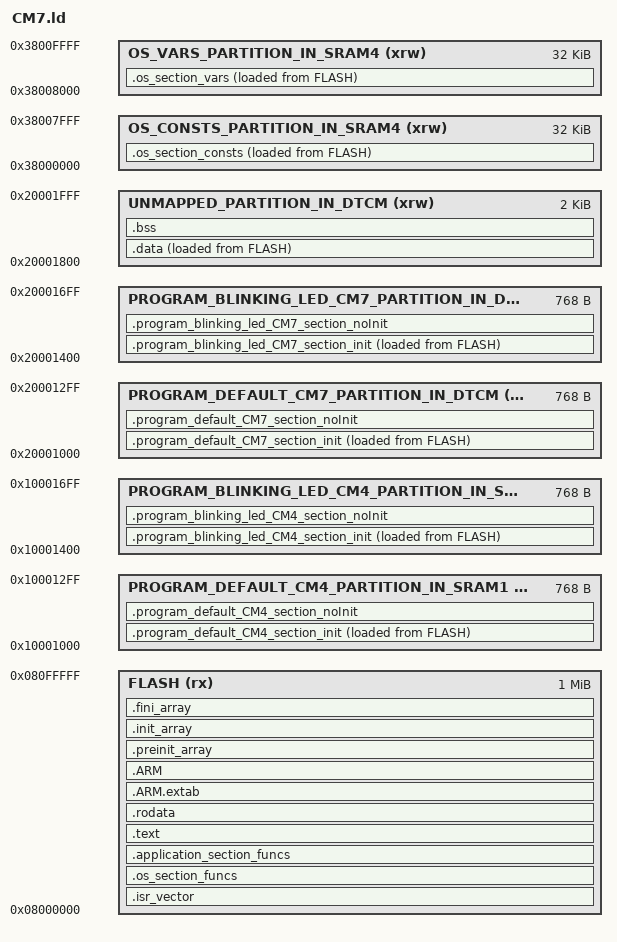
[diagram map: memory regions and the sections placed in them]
/********************************************************************************
**                                                                             **
**                       GENERATED FILE BY CosmOS CustomBox                    **
**                                                                             **
*********************************************************************************
**                       DOXYGEN DOCUMENTATION INFORMATION                     **
*****************************************************************************//**
** @file CM7.ld
*********************************************************************************
<!--                      Linker Local Group Definition                       -->
*********************************************************************************
** @brief CM7 arm gnu linker script
** @details lorem
*********************************************************************************
<!--                           Version Information                            -->
*********************************************************************************
** @version 2.0.0
** @date 2021-09-08
** @author Generated by CosmOS CustomBox
********************************************************************************/

ENTRY(Reset_Handler)

_estack = 0x20020000;

MEMORY
{
FLASH (rx)      : ORIGIN = 0x8000000, LENGTH = 0x100000
UNMAPPED_PARTITION_IN_DTCM (xrw)     : ORIGIN = 0x20001800, LENGTH = 0x0800
OS_CONSTS_PARTITION_IN_SRAM4 (xrw)     : ORIGIN = 0x38000000, LENGTH = 0x8000
OS_VARS_PARTITION_IN_SRAM4 (xrw)     : ORIGIN = 0x38008000, LENGTH = 0x8000
PROGRAM_DEFAULT_CM7_PARTITION_IN_DTCM (xrw)     : ORIGIN = 0x20001000, LENGTH = 0x0300
PROGRAM_BLINKING_LED_CM7_PARTITION_IN_DTCM (xrw)     : ORIGIN = 0x20001400, LENGTH = 0x0300
PROGRAM_DEFAULT_CM4_PARTITION_IN_SRAM1 (xrw)     : ORIGIN = 0x10001000, LENGTH = 0x0300
PROGRAM_BLINKING_LED_CM4_PARTITION_IN_SRAM1 (xrw)     : ORIGIN = 0x10001400, LENGTH = 0x0300
}

SECTIONS
{
  /* The startup code goes first into FLASH */
  .isr_vector :
  {
    . = ALIGN(4);
    KEEP(*(.isr_vector)) /* Startup code */
    . = ALIGN(4);
  } >FLASH

_flash_program_default_CM7_section_init = LOADADDR(.program_default_CM7_section_init);

  /* Init section */
  .program_default_CM7_section_init :
  {
    . = ALIGN(4);
    _s_program_default_CM7_section_init = .;          /* create a global symbol at section start */
    KEEP(*(.default_CM7_init));
    . = ALIGN(4);
    _e_program_default_CM7_section_init = .;          /* create a global symbol at section end */
  } >PROGRAM_DEFAULT_CM7_PARTITION_IN_DTCM AT> FLASH

  /* No init section */
  .program_default_CM7_section_noInit :
  {
    . = ALIGN(4);
    KEEP(*(.default_CM7_noInit));
    . = ALIGN(4);
  } >PROGRAM_DEFAULT_CM7_PARTITION_IN_DTCM
_flash_program_blinking_led_CM7_section_init = LOADADDR(.program_blinking_led_CM7_section_init);

  /* Init section */
  .program_blinking_led_CM7_section_init :
  {
    . = ALIGN(4);
    _s_program_blinking_led_CM7_section_init = .;          /* create a global symbol at section start */
    KEEP(*(.blinking_led_CM7_init));
    . = ALIGN(4);
    _e_program_blinking_led_CM7_section_init = .;          /* create a global symbol at section end */
  } >PROGRAM_BLINKING_LED_CM7_PARTITION_IN_DTCM AT> FLASH

  /* No init section */
  .program_blinking_led_CM7_section_noInit :
  {
    . = ALIGN(4);
    KEEP(*(.blinking_led_CM7_noInit));
    . = ALIGN(4);
  } >PROGRAM_BLINKING_LED_CM7_PARTITION_IN_DTCM
_flash_program_default_CM4_section_init = LOADADDR(.program_default_CM4_section_init);

  /* Init section */
  .program_default_CM4_section_init :
  {
    . = ALIGN(4);
    _s_program_default_CM4_section_init = .;          /* create a global symbol at section start */
    KEEP(*(.default_CM4_init));
    . = ALIGN(4);
    _e_program_default_CM4_section_init = .;          /* create a global symbol at section end */
  } >PROGRAM_DEFAULT_CM4_PARTITION_IN_SRAM1 AT> FLASH

  /* No init section */
  .program_default_CM4_section_noInit :
  {
    . = ALIGN(4);
    KEEP(*(.default_CM4_noInit));
    . = ALIGN(4);
  } >PROGRAM_DEFAULT_CM4_PARTITION_IN_SRAM1
_flash_program_blinking_led_CM4_section_init = LOADADDR(.program_blinking_led_CM4_section_init);

  /* Init section */
  .program_blinking_led_CM4_section_init :
  {
    . = ALIGN(4);
    _s_program_blinking_led_CM4_section_init = .;          /* create a global symbol at section start */
    KEEP(*(.blinking_led_CM4_init));
    . = ALIGN(4);
    _e_program_blinking_led_CM4_section_init = .;          /* create a global symbol at section end */
  } >PROGRAM_BLINKING_LED_CM4_PARTITION_IN_SRAM1 AT> FLASH

  /* No init section */
  .program_blinking_led_CM4_section_noInit :
  {
    . = ALIGN(4);
    KEEP(*(.blinking_led_CM4_noInit));
    . = ALIGN(4);
  } >PROGRAM_BLINKING_LED_CM4_PARTITION_IN_SRAM1
_flash_os_section_consts_start = LOADADDR(.os_section_consts);

  /* Initialized data sections goes into RAM, load LMA copy after code */
  .os_section_consts :
  {
    . = ALIGN(4);
    _s_os_section_consts = .;          /* create a global symbol at data start */
	KEEP (*(SORT(.os_consts.*)));
    KEEP (*(.os_consts*));
    _e_consts_align_helper = .;        /* create a helper for log2 alignment */
    . = ALIGN((0x2 << (LOG2CEIL (_e_consts_align_helper) - 1)));
    _e_os_section_consts = .;          /* create a global symbol at data end */
  } >OS_CONSTS_PARTITION_IN_SRAM4 AT> FLASH
_flash_os_section_vars_start = LOADADDR(.os_section_vars);

  /* Initialized data sections goes into RAM, load LMA copy after code */
  .os_section_vars :
  {
    . = ALIGN(4);
    _s_os_section_vars = .;          /* create a global symbol at data start */
	KEEP (*(SORT(.os_vars.*)));
    KEEP (*(.os_vars*));
    _e_vars_align_helper = .;        /* create a helper for log2 alignment */
    . = ALIGN((0x2 << (LOG2CEIL (_e_vars_align_helper) - 1)));
    _e_os_section_vars = .;          /* create a global symbol at data end */
  } >OS_VARS_PARTITION_IN_SRAM4 AT> FLASH
/* FLASH */
    .os_section_funcs :
  {
    . = ALIGN(4);
    KEEP(*(.os_funcs));
    . = ALIGN(4);
  } > FLASH

  /* FLASH */
    .application_section_funcs :
  {
    . = ALIGN(4);
    KEEP(*(.application_funcs));
    . = ALIGN(4);
  } > FLASH

  /* The program code and other data goes into FLASH */
  .text :
  {
    . = ALIGN(4);
    *(.text)           /* .text sections (code) */
    *(.text*)          /* .text* sections (code) */
    *(.glue_7)         /* glue arm to thumb code */
    *(.glue_7t)        /* glue thumb to arm code */
    *(.eh_frame)

    KEEP (*(.init))
    KEEP (*(.fini))

    . = ALIGN(4);
    _etext = .;        /* define a global symbols at end of code */
  } >FLASH

  /* Constant data goes into FLASH */
  .rodata :
  {
    . = ALIGN(4);
    *(.rodata)         /* .rodata sections (constants, strings, etc.) */
    *(.rodata*)        /* .rodata* sections (constants, strings, etc.) */
    . = ALIGN(4);
  } >FLASH

  .ARM.extab   : { *(.ARM.extab* .gnu.linkonce.armextab.*) } >FLASH
  .ARM : {
    __exidx_start = .;
    *(.ARM.exidx*)
    __exidx_end = .;
  } >FLASH

  .preinit_array     :
  {
    PROVIDE_HIDDEN (__preinit_array_start = .);
    KEEP (*(.preinit_array*))
    PROVIDE_HIDDEN (__preinit_array_end = .);
  } >FLASH
  .init_array :
  {
    PROVIDE_HIDDEN (__init_array_start = .);
    KEEP (*(SORT(.init_array.*)))
    KEEP (*(.init_array*))
    PROVIDE_HIDDEN (__init_array_end = .);
  } >FLASH
  .fini_array :
  {
    PROVIDE_HIDDEN (__fini_array_start = .);
    KEEP (*(SORT(.fini_array.*)))
    KEEP (*(.fini_array*))
    PROVIDE_HIDDEN (__fini_array_end = .);
  } >FLASH

  /* used by the startup to initialize data */
  _sidata = LOADADDR(.data);

  /* Initialized data sections goes into RAM, load LMA copy after code */
  .data :
  {
    . = ALIGN(4);
	_s_unprotected_section = .;          /* create a global symbol at data start */
    _sdata = .;        /* create a global symbol at data start */
    *(.data)           /* .data sections */
    *(.data*)          /* .data* sections */

    . = ALIGN(4);
    _edata = .;        /* define a global symbol at data end */
  } >UNMAPPED_PARTITION_IN_DTCM AT> FLASH


  /* Uninitialized data section */
  . = ALIGN(4);
  .bss :
  {
    /* This is used by the startup in order to initialize the .bss secion */
    _sbss = .;         /* define a global symbol at bss start */
    __bss_start__ = _sbss;
    *(.bss)
    *(.bss*)
    *(COMMON)

    . = ALIGN(4);
    _ebss = .;         /* define a global symbol at bss end */
    __bss_end__ = _ebss;
	_e_unprotected_align_helper = .;        /* create a helper for log2 alignment */
    . = ALIGN((0x2 << (LOG2CEIL (_e_unprotected_align_helper) - 1)));
	_e_unprotected_section = .;          /* create a global symbol at data start */
  } >UNMAPPED_PARTITION_IN_DTCM

  /* Remove information from the standard libraries */
  /DISCARD/ :
  {
    libc.a ( * )
    libm.a ( * )
    libgcc.a ( * )
    *(.program_default_CM4_section_init*)
    *(.program_default_CM4_section_noInit*)
    *(.program_blinking_led_CM4_section_init*)
    *(.program_blinking_led_CM4_section_noInit*)
    }

  .ARM.attributes 0 : { *(.ARM.attributes) }
}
